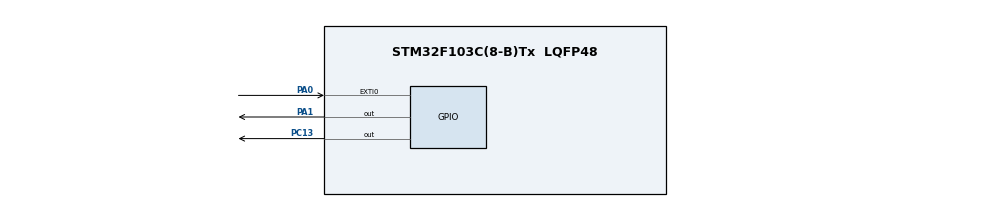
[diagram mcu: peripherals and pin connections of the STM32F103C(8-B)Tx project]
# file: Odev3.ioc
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Mcu.Family=STM32F1
Mcu.Name=STM32F103C(8-B)Tx
Mcu.Package=LQFP48
NVIC.EXTI0_IRQn=true\:0\:0\:false\:false\:true\:true\:true\:true
NVIC.PriorityGroup=NVIC_PRIORITYGROUP_4
NVIC.TIM2_IRQn=true\:0\:0\:false\:false\:true\:true\:true\:true
PA0-WKUP.GPIO_ModeDefaultEXTI=GPIO_MODE_IT_FALLING
PA0-WKUP.GPIO_PuPd=GPIO_PULLUP
PA0-WKUP.Signal=GPXTI0
PA1.Signal=GPIO_Output
PA13.Mode=Serial_Wire
PA13.Signal=SYS_JTMS-SWDIO
PA14.Mode=Serial_Wire
PA14.Signal=SYS_JTCK-SWCLK
PC13-TAMPER-RTC.Signal=GPIO_Output
PD0-OSC_IN.Mode=HSE-External-Oscillator
PD0-OSC_IN.Signal=RCC_OSC_IN
PD1-OSC_OUT.Mode=HSE-External-Oscillator
PD1-OSC_OUT.Signal=RCC_OSC_OUT
ProjectManager.HeapSize=0x200
ProjectManager.StackSize=0x400
ProjectManager.TargetToolchain=Makefile
RCC.APB1Freq_Value=8000000
RCC.APB2Freq_Value=8000000
TIM2.Period=999
TIM2.Prescaler=7999
VP_TIM2_VS_ClockSourceINT.Mode=Internal
board=custom

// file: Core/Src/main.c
/* USER CODE BEGIN Header */
/**
  ******************************************************************************
  * @file           : main.c
  * @brief          : Main program body
  ******************************************************************************
  */
/* USER CODE END Header */
#include "main.h"

/* USER CODE BEGIN Includes */
#include "stm32f1xx_hal_flash.h"
/* USER CODE END Includes */

TIM_HandleTypeDef htim2;

/* USER CODE BEGIN PV */
uint32_t blink_count = 4;
uint32_t current_blink = 0;
uint32_t timer_seconds = 0;
uint8_t is_5sec_wait = 0;

unsigned int prev_tick_count = 0;

#define FLASH_USER_ADDR 0x0800FC00
/* USER CODE END PV */

void SystemClock_Config(void);
static void MX_GPIO_Init(void);
static void MX_TIM2_Init(void);

/* USER CODE BEGIN 0 */
uint32_t ReadFlash(void) {
    return *(volatile uint32_t*)FLASH_USER_ADDR;
}

void WriteFlash(uint32_t data) {
    HAL_FLASH_Unlock();
    FLASH_EraseInitTypeDef EraseInitStruct;
    uint32_t PageError;
    EraseInitStruct.TypeErase = FLASH_TYPEERASE_PAGES;
    EraseInitStruct.PageAddress = FLASH_USER_ADDR;
    EraseInitStruct.NbPages = 1;
    HAL_FLASHEx_Erase(&EraseInitStruct, &PageError);
    HAL_FLASH_Program(FLASH_TYPEPROGRAM_WORD, FLASH_USER_ADDR, data);
    HAL_FLASH_Lock();
}
/* USER CODE END 0 */

int main(void)
{
  HAL_Init();
  SystemClock_Config();
  MX_GPIO_Init();
  MX_TIM2_Init();

/* USER CODE BEGIN 2 */

  // PA1 = Земля
  HAL_GPIO_WritePin(GPIOA, GPIO_PIN_1, GPIO_PIN_RESET);

  blink_count = ReadFlash();
  if (blink_count < 4 || blink_count > 6) {
      blink_count = 4;
      WriteFlash(blink_count);
  }

  // АППАРАТНЫЙ СБРОС (Пункт G)
  uint32_t press_start = HAL_GetTick();
  while (HAL_GPIO_ReadPin(GPIOA, GPIO_PIN_0) == GPIO_PIN_RESET) {
      if (HAL_GetTick() - press_start >= 3000) {
          blink_count = 4;
          WriteFlash(blink_count);
          for(int i=0; i<6; i++) {
              HAL_GPIO_TogglePin(GPIOC, GPIO_PIN_13);
              HAL_Delay(100);
          }
          break; // Выходим из цикла СРАЗУ. Никаких зависаний.
      }
  }

  HAL_GPIO_WritePin(GPIOC, GPIO_PIN_13, GPIO_PIN_SET);

  // Защита от искр при старте
  prev_tick_count = HAL_GetTick();
  HAL_TIM_Base_Start_IT(&htim2);

/* USER CODE END 2 */

  while (1)
  {
  }
}

void SystemClock_Config(void)
{
  RCC_OscInitTypeDef RCC_OscInitStruct = {0};
  RCC_ClkInitTypeDef RCC_ClkInitStruct = {0};

  RCC_OscInitStruct.OscillatorType = RCC_OSCILLATORTYPE_HSI;
  RCC_OscInitStruct.HSIState = RCC_HSI_ON;
  RCC_OscInitStruct.HSICalibrationValue = RCC_HSICALIBRATION_DEFAULT;
  RCC_OscInitStruct.PLL.PLLState = RCC_PLL_NONE;
  if (HAL_RCC_OscConfig(&RCC_OscInitStruct) != HAL_OK) { Error_Handler(); }

  RCC_ClkInitStruct.ClockType = RCC_CLOCKTYPE_HCLK|RCC_CLOCKTYPE_SYSCLK
                              |RCC_CLOCKTYPE_PCLK1|RCC_CLOCKTYPE_PCLK2;
  RCC_ClkInitStruct.SYSCLKSource = RCC_SYSCLKSOURCE_HSI;
  RCC_ClkInitStruct.AHBCLKDivider = RCC_SYSCLK_DIV1;
  RCC_ClkInitStruct.APB1CLKDivider = RCC_HCLK_DIV1;
  RCC_ClkInitStruct.APB2CLKDivider = RCC_HCLK_DIV1;

  if (HAL_RCC_ClockConfig(&RCC_ClkInitStruct, FLASH_LATENCY_0) != HAL_OK) { Error_Handler(); }
}

static void MX_TIM2_Init(void)
{
  TIM_ClockConfigTypeDef sClockSourceConfig = {0};
  TIM_MasterConfigTypeDef sMasterConfig = {0};

  htim2.Instance = TIM2;
  htim2.Init.Prescaler = 7999;
  htim2.Init.CounterMode = TIM_COUNTERMODE_UP;
  htim2.Init.Period = 999;
  htim2.Init.ClockDivision = TIM_CLOCKDIVISION_DIV1;
  htim2.Init.AutoReloadPreload = TIM_AUTORELOAD_PRELOAD_DISABLE;
  if (HAL_TIM_Base_Init(&htim2) != HAL_OK) { Error_Handler(); }
  sClockSourceConfig.ClockSource = TIM_CLOCKSOURCE_INTERNAL;
  if (HAL_TIM_ConfigClockSource(&htim2, &sClockSourceConfig) != HAL_OK) { Error_Handler(); }
  sMasterConfig.MasterOutputTrigger = TIM_TRGO_RESET;
  sMasterConfig.MasterSlaveMode = TIM_MASTERSLAVEMODE_DISABLE;
  if (HAL_TIMEx_MasterConfigSynchronization(&htim2, &sMasterConfig) != HAL_OK) { Error_Handler(); }
}

static void MX_GPIO_Init(void)
{
  GPIO_InitTypeDef GPIO_InitStruct = {0};

  __HAL_RCC_GPIOC_CLK_ENABLE();
  __HAL_RCC_GPIOD_CLK_ENABLE();
  __HAL_RCC_GPIOA_CLK_ENABLE();

  HAL_GPIO_WritePin(GPIOC, GPIO_PIN_13, GPIO_PIN_RESET);
  HAL_GPIO_WritePin(GPIOA, GPIO_PIN_1, GPIO_PIN_RESET);

  GPIO_InitStruct.Pin = GPIO_PIN_13;
  GPIO_InitStruct.Mode = GPIO_MODE_OUTPUT_PP;
  GPIO_InitStruct.Pull = GPIO_NOPULL;
  GPIO_InitStruct.Speed = GPIO_SPEED_FREQ_LOW;
  HAL_GPIO_Init(GPIOC, &GPIO_InitStruct);

  GPIO_InitStruct.Pin = GPIO_PIN_0;
  GPIO_InitStruct.Mode = GPIO_MODE_IT_FALLING;
  GPIO_InitStruct.Pull = GPIO_PULLUP;
  HAL_GPIO_Init(GPIOA, &GPIO_InitStruct);

  GPIO_InitStruct.Pin = GPIO_PIN_1;
  GPIO_InitStruct.Mode = GPIO_MODE_OUTPUT_PP;
  GPIO_InitStruct.Pull = GPIO_NOPULL;
  GPIO_InitStruct.Speed = GPIO_SPEED_FREQ_LOW;
  HAL_GPIO_Init(GPIOA, &GPIO_InitStruct);

  HAL_NVIC_SetPriority(EXTI0_IRQn, 0, 0);
  HAL_NVIC_EnableIRQ(EXTI0_IRQn);
}

/* USER CODE BEGIN 4 */

void HAL_TIM_PeriodElapsedCallback(TIM_HandleTypeDef *htim) {
    if (htim->Instance == TIM2) {
        if (is_5sec_wait) {
            timer_seconds++;
            if (timer_seconds >= 5) {
                is_5sec_wait = 0;
                current_blink = 0;
            }
        } else {
            if (current_blink < blink_count * 2) {
                HAL_GPIO_TogglePin(GPIOC, GPIO_PIN_13);
                current_blink++;
            } else {
                HAL_GPIO_WritePin(GPIOC, GPIO_PIN_13, GPIO_PIN_SET);
                is_5sec_wait = 1;
                timer_seconds = 0;
            }
        }
    }
}

void HAL_GPIO_EXTI_Callback(uint16_t GPIO_Pin)
{
    if(GPIO_Pin == GPIO_PIN_0)
    {
        unsigned int cur_tick_count = HAL_GetTick();

        // 1. Стандартная защита от слишком частых нажатий (1 секунда)
        if(cur_tick_count - prev_tick_count < 1000) return;

        // 2. Ждем крошечную долю секунды, чтобы искры провода физически пролетели
        for(volatile int i=0; i<10000; i++) { }

        // 3. ФИЗИЧЕСКАЯ ПРОВЕРКА: Если сейчас провод НЕ касается контакта (видит HIGH),
        // значит это была искра от того, что ты его вытащила. Жестко игнорируем!
        if(HAL_GPIO_ReadPin(GPIOA, GPIO_PIN_0) == GPIO_PIN_SET) return;

        // Если дошли сюда, значит провод реально замкнут.
        prev_tick_count = cur_tick_count;

        blink_count++;
        if (blink_count > 6) {
            blink_count = 4;
        }
        WriteFlash(blink_count);

        current_blink = 0;
        is_5sec_wait = 0;
        timer_seconds = 0;
    }
}

/* USER CODE END 4 */

void Error_Handler(void) {
  __disable_irq();
  while (1) {}
}
